# MS32Cxxx_DFP register map
Vendor: MS; Series: MS32C; File version: 1.0.0
CPU: CM0+ r0p1, little endian, no MPU, no FPU, 4 interrupt priority bits
Registers are 32-bit, read-write, reset 0x0 unless marked. A register's access mark holds for its fields unless they carry their own. Offsets are from the block's base; [hi:lo] are bit positions; {n}, {i} and the like mark numbered series.

## LPTIM1 — Low power timer
Base 0x40007C00
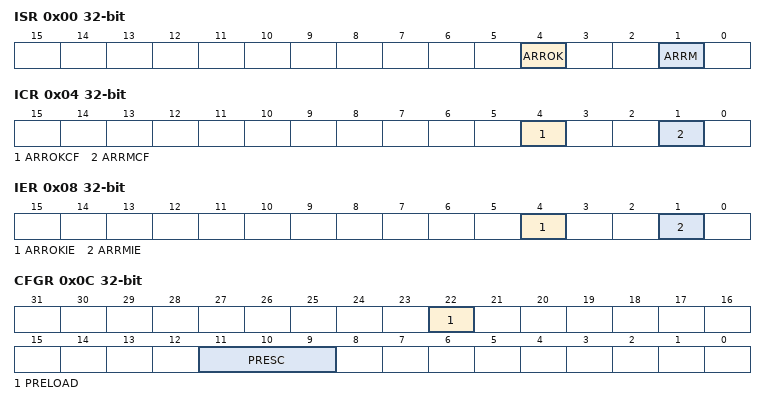
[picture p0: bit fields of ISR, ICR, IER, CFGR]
0x00 ISR ro — Interrupt and Status Register
  [4] ARROK — Autoreload match update OK
  [1] ARRM — Autoreload match
0x04 ICR wo — Interrupt Clear Register
  [4] ARROKCF — Autoreload match update OK Clear Flag
  [1] ARRMCF — Autoreload match Clear Flag
0x08 IER — Interrupt Enable Register
  [4] ARROKIE — Autoreload match update OK Interrupt Enable
  [1] ARRMIE — Autoreload matchInterrupt Enable
0x0C CFGR — Configuration Register
  [22] PRELOAD — Registers update mode
  [11:9] PRESC — Clock prescaler
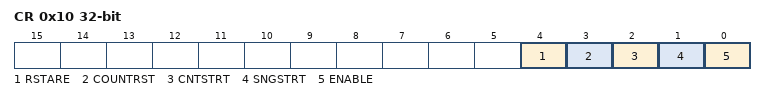
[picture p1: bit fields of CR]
0x10 CR — Control Register
  [4] RSTARE — Reset after read enable
  [3] COUNTRST — Reset counter
  [2] CNTSTRT
  [1] SNGSTRT — LPTIM start in single mode
  [0] ENABLE — LPTIM Enable
0x18 ARR reset 0x1 — Autoreload Register
  [15:0] ARR — Auto reload value
0x1C CNT ro — Counter Register
  [15:0] CNT — Counter value

## IWDG — Independent watchdog
Base 0x40003000
0x00 KR wo — Key register (IWDG_KR)
  [15:0] KEY — Key value
0x04 PR — Prescaler register (IWDG_PR)
  [2:0] PR — Prescaler divider
0x08 RLR reset 0xFFF — Reload register (IWDG_RLR)
  [11:0] RL — Watchdog counter reload value
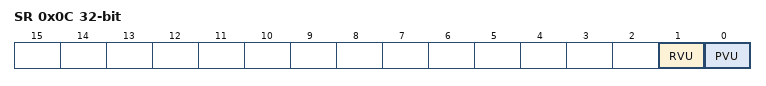
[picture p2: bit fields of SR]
0x0C SR ro — Status register (IWDG_SR)
  [1] RVU — Watchdog counter reload value update
  [0] PVU — Watchdog prescaler value update

## TIM1 — Advanced timer
Base 0x40012C00
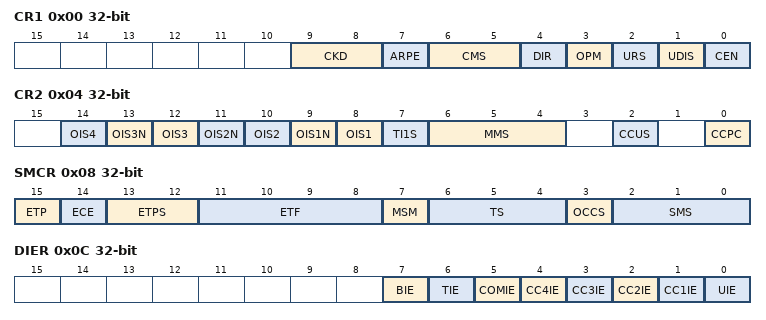
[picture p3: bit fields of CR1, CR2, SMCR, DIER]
0x00 CR1
  [9:8] CKD, [7] ARPE, [6:5] CMS, [4] DIR, [3] OPM, [2] URS, [1] UDIS, [0] CEN
0x04 CR2 (reset mask 0xF8)
  [2n+6] OIS{n} (n=1..4), [13] OIS3N, [11] OIS2N, [9] OIS1N, [7] TI1S, [6:4] MMS, [2] CCUS, [0] CCPC
0x08 SMCR (reset mask 0xFFF7)
  [15] ETP, [14] ECE, [13:12] ETPS, [11:8] ETF, [7] MSM, [6:4] TS, [3] OCCS, [2:0] SMS
0x0C DIER (reset mask 0x5F5F)
  [7] BIE, [6] TIE, [5] COMIE, [n] CC{n}IE (n=1..4), [0] UIE
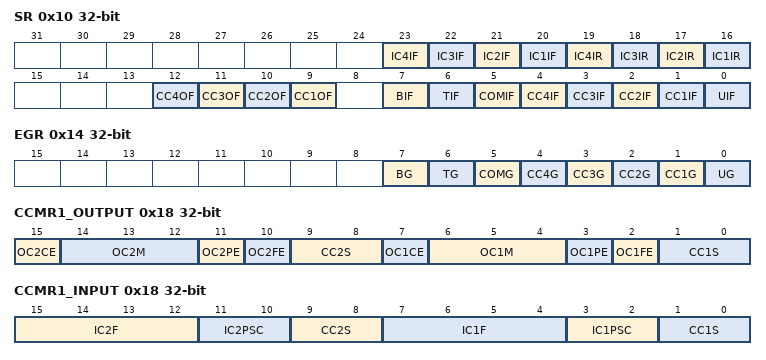
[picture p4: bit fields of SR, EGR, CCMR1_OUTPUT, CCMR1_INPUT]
0x10 SR (reset mask 0x1E5F)
  [23] IC4IF — desc IC3IF
  [22] IC3IF
  [21] IC2IF
  [20] IC1IF
  [19] IC4IR — desc IC3IR
  [18] IC3IR
  [17] IC2IR
  [16] IC1IR
  [n+8] CC{n}OF (n=1..4)
  [7] BIF
  [6] TIF
  [5] COMIF
  [n] CC{n}IF (n=1..4)
  [0] UIF
0x14 EGR wo (reset mask 0x5F)
  [7] BG
  [6] TG
  [5] COMG
  [4] CC4G
  [3] CC3G
  [2] CC2G
  [1] CC1G — Capture/Compare 1 Generation
  [0] UG
0x18 CCMR1_OUTPUT
  [15] OC2CE, [14:12] OC2M, [11] OC2PE, [10] OC2FE, [9:8] CC2S, [7] OC1CE, [6:4] OC1M, [3] OC1PE, [2] OC1FE, [1:0] CC1S
0x18 CCMR1_INPUT (alternate view of CCMR1_OUTPUT)
  [15:12] IC2F, [11:10] IC2PSC, [9:8] CC2S, [7:4] IC1F, [3:2] IC1PSC, [1:0] CC1S
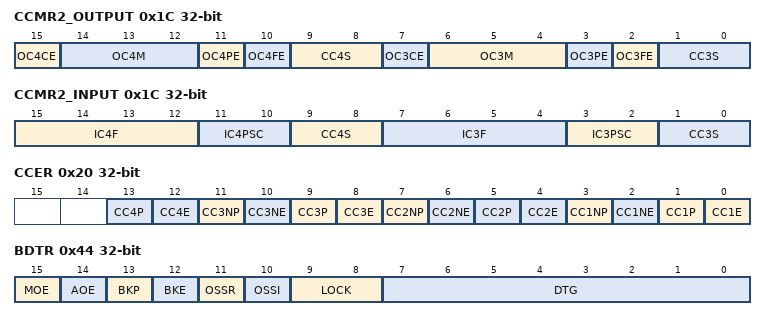
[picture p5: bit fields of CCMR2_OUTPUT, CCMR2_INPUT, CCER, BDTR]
0x1C CCMR2_OUTPUT
  [15] OC4CE, [14:12] OC4M, [11] OC4PE, [10] OC4FE, [9:8] CC4S, [7] OC3CE, [6:4] OC3M, [3] OC3PE, [2] OC3FE, [1:0] CC3S
0x1C CCMR2_INPUT (alternate view of CCMR2_OUTPUT)
  [15:12] IC4F, [11:10] IC4PSC, [9:8] CC4S, [7:4] IC3F, [3:2] IC3PSC, [1:0] CC3S
0x20 CCER (reset mask 0x3333)
  [4n-3] CC{n}P (n=1..4), [4n-4] CC{n}E (n=1..4), [11] CC3NP, [10] CC3NE, [7] CC2NP, [6] CC2NE, [3] CC1NP, [2] CC1NE
0x24 CNT
  [15:0] CNT
0x28 PSC
  [15:0] PSC
0x2C ARR reset 0xFFFF
  [15:0] ARR
0x30 RCR reset 0xFFFF
  [7:0] REP
{0x30+4i} CCR{i} (i=1..4)
  [15:0] CCR{i}
0x44 BDTR
  [15] MOE, [14] AOE, [13] BKP, [12] BKE, [11] OSSR, [10] OSSI, [9:8] LOCK, [7:0] DTG

## TIM14 — General purpose timer
Base 0x40002000
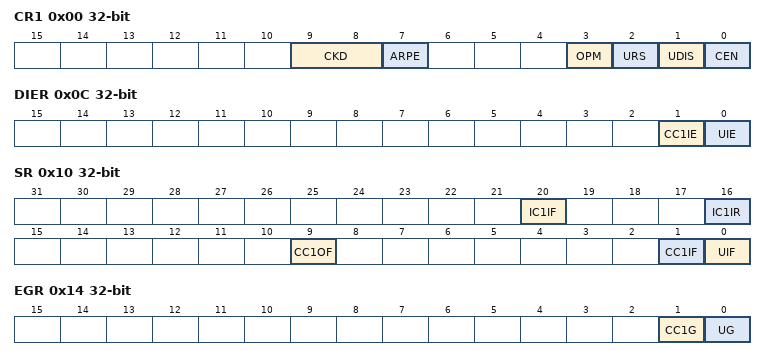
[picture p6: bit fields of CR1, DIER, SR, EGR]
0x00 CR1
  [9:8] CKD, [7] ARPE, [3] OPM, [2] URS, [1] UDIS, [0] CEN
0x0C DIER
  [1] CC1IE, [0] UIE
0x10 SR (reset mask 0x1E5F)
  [20] IC1IF, [16] IC1IR, [9] CC1OF, [1] CC1IF, [0] UIF
0x14 EGR wo
  [1] CC1G — Capture/Compare 1 Generation
  [0] UG
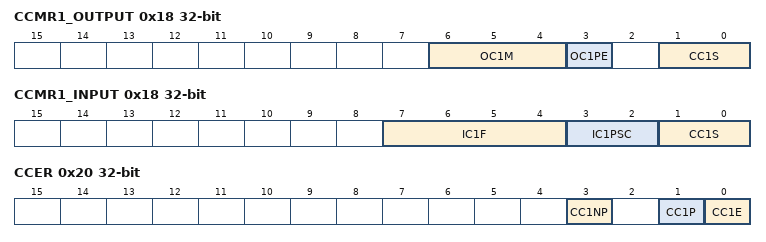
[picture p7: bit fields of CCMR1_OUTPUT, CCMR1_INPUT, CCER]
0x18 CCMR1_OUTPUT
  [6:4] OC1M, [3] OC1PE, [1:0] CC1S
0x18 CCMR1_INPUT (alternate view of CCMR1_OUTPUT)
  [7:4] IC1F, [3:2] IC1PSC, [1:0] CC1S
0x20 CCER (reset mask 0x3333)
  [3] CC1NP, [1] CC1P, [0] CC1E
0x24 CNT
  [15:0] CNT
0x28 PSC
  [15:0] PSC
0x2C ARR reset 0xFFFF
  [15:0] ARR
0x34 CCR1
  [15:0] CCR1
0x50 OR
  [1:0] TI1_RMP

## SYSCFG — System configuration controller
Base 0x40010000
0x00 CFGR1 — SYSCFG configuration register 1
  [1:0] MEM_MODE — Memory mapping selection bits
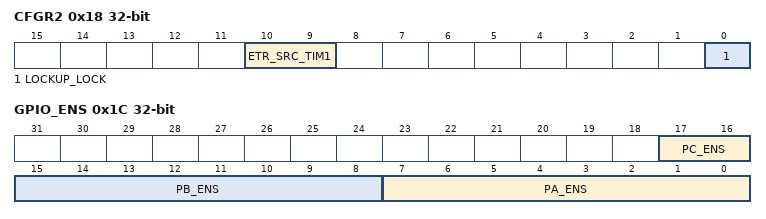
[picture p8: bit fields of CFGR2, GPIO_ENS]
0x18 CFGR2 — SYSCFG configuration register 2
  [10:9] ETR_SRC_TIM1 — TIM1 ETR source selection
  [0] LOCKUP_LOCK — Cortex-M0+ LOCKUP bit enable bit
0x1C GPIO_ENS
  [17:16] PC_ENS, [15:8] PB_ENS, [7:0] PA_ENS

## FLASH
Base 0x40022000
0x00 ACR reset 0x600 — Access control register
  [0] LATENCY
0x08 KEYR wo — Flash key register
  [31:0] KEY — Flash key
0x0C OPTKEYR wo — Option byte key register
  [31:0] OPTKEY — Option byte key
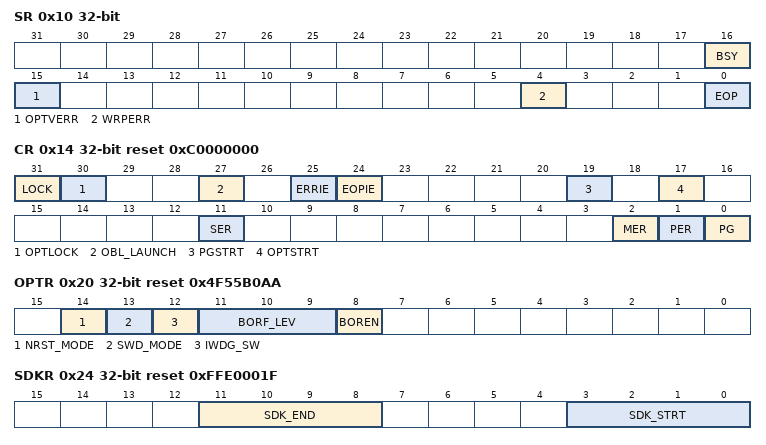
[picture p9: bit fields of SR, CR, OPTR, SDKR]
0x10 SR — Status register
  [16] BSY — Busy
  [15] OPTVERR — Option and Engineering bits loading validity error
  [4] WRPERR — Write protected error
  [0] EOP — End of operation
0x14 CR reset 0xC0000000 — Flash control register
  [31] LOCK — FLASH_CR Lock
  [30] OPTLOCK — Options Lock
  [27] OBL_LAUNCH — Force the option byte loading
  [25] ERRIE — Error interrupt enable
  [24] EOPIE — End of operation interrupt enable
  [19] PGSTRT — Flash main memory program start
  [17] OPTSTRT — Option byte program start
  [11] SER — Sector erase
  [2] MER — Mass erase
  [1] PER — Page erase
  [0] PG — Programming
0x20 OPTR reset 0x4F55B0AA — Flash option register
  [14] NRST_MODE
  [13] SWD_MODE
  [12] IWDG_SW — Independent watchdog selection
  [11:9] BORF_LEV — These bits contain the VDD supply level threshold that activates the reset
  [8] BOREN — BOR reset Level
0x24 SDKR reset 0xFFE0001F — Flash SDK address register
  [11:8] SDK_END — SDK area end address
  [3:0] SDK_STRT — SDK area start address
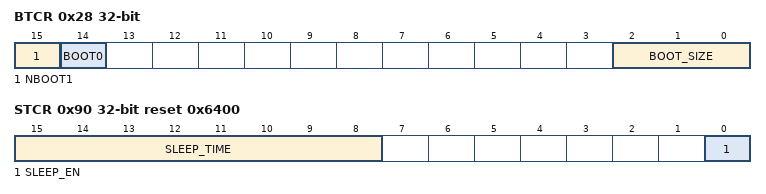
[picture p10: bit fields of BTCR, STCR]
0x28 BTCR — FLASH boot control register
  [15] NBOOT1, [14] BOOT0, [2:0] BOOT_SIZE
0x2C WRPR reset 0xFFFF — Flash WRP address register
  [5:0] WRP — WRP address
0x90 STCR reset 0x6400 — Flash sleep time config register
  [15:8] SLEEP_TIME — FLash sleep time configuration(counter based on HSI_10M)
  [0] SLEEP_EN — FLash sleep enable
0x100 TS0 reset 0xB4 — Flash TS0 register
  [8:0] TS0 — FLash TS0 register
0x104 TS1 reset 0x1B0 — Flash TS1 register
  [9:0] TS1 — FLash TS1 register
0x108 TS2P reset 0xB4 — Flash TS2P register
  [8:0] TS2P — FLash TS2P register
0x10C TPS3 reset 0x6C0 — Flash TPS3 register
  [11:0] TPS3 — FLash TPS3 register
0x110 TS3 reset 0xB4 — Flash TS3 register
  [8:0] TS3 — FLash TS3 register
0x114 PERTPE reset 0x14820 — Flash PERTPE register
  [17:0] PERTPE — FLash PERTPE register
0x118 SMERTPE reset 0x14820 — Flash SMERTPE register
  [17:0] SMERTPE — FLash SMERTPE register
0x11C PRGTPE reset 0x5DC0 — Flash PRGTPE register
  [15:0] PRGTPE — FLash PRGTPE register
0x120 PRETPE reset 0x12C0 — Flash PRETPE register
  [13:0] PRETPE — FLash PRETPE register

## CRC — CRC calculation unit
Base 0x40023000
0x00 DR reset 0xFFFFFFFF — Data register
  [31:0] DR — Data Register
0x04 IDR — Independent Data register
  [7:0] IDR
0x08 CR wo — Control register
  [0] RESET — Reset bit

## DBGMCU — Debug support
Base 0x40015800
0x00 IDCODE ro — MCU Device ID Code Register
  [31:0] REV_ID
0x04 CR — Debug MCU Configuration Register
  [1] DBG_STOP — Debug Stop Mode
0x08 APB_FZ1 — APB Freeze Register1
  [31] DBG_LPTIM_STOP — Debug LPTIM stopped when Core ishalted
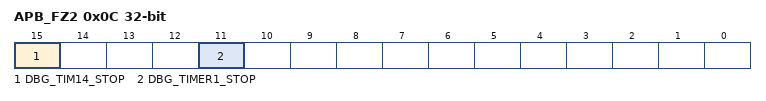
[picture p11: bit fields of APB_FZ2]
0x0C APB_FZ2 — APB Freeze Register2
  [15] DBG_TIM14_STOP — Debug TIM 14 stopped whenCore is halted
  [11] DBG_TIMER1_STOP — Debug Timer 1 stopped when Core ishalted
